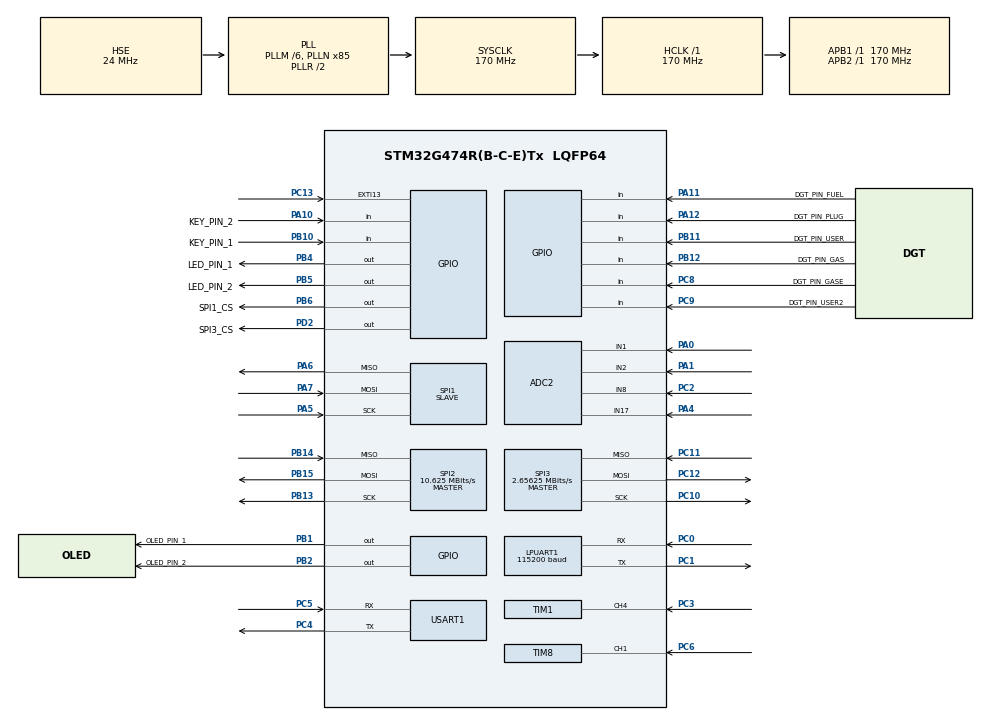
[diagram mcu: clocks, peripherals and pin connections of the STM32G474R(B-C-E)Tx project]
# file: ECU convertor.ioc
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ADC2.Channel-0\#ChannelRegularConversion=ADC_CHANNEL_1
ADC2.Channel-1\#ChannelRegularConversion=ADC_CHANNEL_2
ADC2.Channel-2\#ChannelRegularConversion=ADC_CHANNEL_8
ADC2.Channel-3\#ChannelRegularConversion=ADC_CHANNEL_17
ADC2.ContinuousConvMode=ENABLE
ADC2.DMAContinuousRequests=ENABLE
ADC2.EnableInjectedConversion=DISABLE
ADC2.NbrOfConversion=4
ADC2.NbrOfConversionFlag=1
ADC2.OffsetNumber-0\#ChannelRegularConversion=ADC_OFFSET_NONE
ADC2.OffsetNumber-1\#ChannelRegularConversion=ADC_OFFSET_NONE
ADC2.OffsetNumber-2\#ChannelRegularConversion=ADC_OFFSET_NONE
ADC2.OffsetNumber-3\#ChannelRegularConversion=ADC_OFFSET_NONE
ADC2.Rank-0\#ChannelRegularConversion=1
ADC2.Rank-1\#ChannelRegularConversion=2
ADC2.Rank-2\#ChannelRegularConversion=3
ADC2.Rank-3\#ChannelRegularConversion=4
ADC2.SamplingTime-0\#ChannelRegularConversion=ADC_SAMPLETIME_2CYCLES_5
ADC2.SamplingTime-1\#ChannelRegularConversion=ADC_SAMPLETIME_2CYCLES_5
ADC2.SamplingTime-2\#ChannelRegularConversion=ADC_SAMPLETIME_2CYCLES_5
ADC2.SamplingTime-3\#ChannelRegularConversion=ADC_SAMPLETIME_2CYCLES_5
Dma.ADC2.0.Direction=DMA_PERIPH_TO_MEMORY
Dma.ADC2.0.EventEnable=DISABLE
Dma.ADC2.0.Instance=DMA1_Channel1
Dma.ADC2.0.MemDataAlignment=DMA_MDATAALIGN_HALFWORD
Dma.ADC2.0.MemInc=DMA_MINC_ENABLE
Dma.ADC2.0.Mode=DMA_CIRCULAR
Dma.ADC2.0.PeriphDataAlignment=DMA_PDATAALIGN_HALFWORD
Dma.ADC2.0.PeriphInc=DMA_PINC_DISABLE
Dma.ADC2.0.Polarity=HAL_DMAMUX_REQ_GEN_RISING
Dma.ADC2.0.Priority=DMA_PRIORITY_LOW
Dma.ADC2.0.RequestNumber=1
Dma.ADC2.0.SignalID=NONE
Dma.ADC2.0.SyncEnable=DISABLE
Dma.ADC2.0.SyncPolarity=HAL_DMAMUX_SYNC_NO_EVENT
Dma.ADC2.0.SyncRequestNumber=1
Dma.ADC2.0.SyncSignalID=NONE
Dma.Request0=ADC2
LPUART1.BaudRate=115200
LPUART1.WordLength=UART_WORDLENGTH_8B
Mcu.Family=STM32G4
Mcu.Name=STM32G474R(B-C-E)Tx
Mcu.Package=LQFP64
NVIC.DMA1_Channel1_IRQn=true\:0\:0\:false\:false\:true\:false\:true
NVIC.EXTI15_10_IRQn=true\:0\:0\:false\:false\:true\:true\:true
NVIC.LPUART1_IRQn=true\:0\:0\:false\:false\:true\:true\:true
NVIC.PriorityGroup=NVIC_PRIORITYGROUP_4
NVIC.SPI1_IRQn=true\:0\:0\:false\:false\:true\:true\:true
NVIC.SPI2_IRQn=true\:0\:0\:false\:false\:true\:true\:true
NVIC.SPI3_IRQn=true\:0\:0\:false\:false\:true\:true\:true
NVIC.TIM6_DAC_IRQn=true\:0\:0\:false\:false\:true\:true\:true
NVIC.USART1_IRQn=true\:0\:0\:false\:false\:true\:true\:true
PA0.Mode=IN1-Single-Ended
PA0.Signal=ADC2_IN1
PA1.Mode=IN2-Single-Ended
PA1.Signal=ADC2_IN2
PA10.GPIO_Label=KEY_PIN_2
PA10.Signal=GPIO_Input
PA11.GPIO_Label=DGT_PIN_FUEL
PA11.Signal=GPIO_Input
PA12.GPIO_Label=DGT_PIN_PLUG
PA12.Signal=GPIO_Input
PA13.Mode=Serial_Wire
PA13.Signal=SYS_JTMS-SWDIO
PA14.Mode=Serial_Wire
PA14.Signal=SYS_JTCK-SWCLK
PA4.Mode=IN17-Single-Ended
PA4.Signal=ADC2_IN17
PA5.Mode=Full_Duplex_Slave
PA5.Signal=SPI1_SCK
PA6.Mode=Full_Duplex_Slave
PA6.Signal=SPI1_MISO
PA7.Mode=Full_Duplex_Slave
PA7.Signal=SPI1_MOSI
PB1.GPIO_Label=OLED_PIN_1
PB1.Signal=GPIO_Output
PB10.GPIO_Label=KEY_PIN_1
PB10.Signal=GPIO_Input
PB11.GPIO_Label=DGT_PIN_USER
PB11.Signal=GPIO_Input
PB12.GPIO_Label=DGT_PIN_GAS
PB12.Signal=GPIO_Input
PB13.Mode=Full_Duplex_Master
PB13.Signal=SPI2_SCK
PB14.Mode=Full_Duplex_Master
PB14.Signal=SPI2_MISO
PB15.Mode=Full_Duplex_Master
PB15.Signal=SPI2_MOSI
PB2.GPIO_Label=OLED_PIN_2
PB2.Signal=GPIO_Output
PB3.Signal=SYS_JTDO-SWO
PB4.GPIO_Label=LED_PIN_1
PB4.Signal=GPIO_Output
PB5.GPIO_Label=LED_PIN_2
PB5.Signal=GPIO_Output
PB6.GPIO_Label=SPI1_CS
PB6.Signal=GPIO_Output
PC0.Mode=Asynchronous
PC0.Signal=LPUART1_RX
PC1.Mode=Asynchronous
PC1.Signal=LPUART1_TX
PC10.Mode=Full_Duplex_Master
PC10.Signal=SPI3_SCK
PC11.Mode=Full_Duplex_Master
PC11.Signal=SPI3_MISO
PC12.Mode=Full_Duplex_Master
PC12.Signal=SPI3_MOSI
PC13.GPIO_ModeDefaultEXTI=GPIO_MODE_IT_RISING
PC13.GPIO_PuPd=GPIO_NOPULL
PC13.Signal=GPXTI13
PC14-OSC32_IN.Mode=LSE-External-Oscillator
PC14-OSC32_IN.Signal=RCC_OSC32_IN
PC15-OSC32_OUT.Mode=LSE-External-Oscillator
PC15-OSC32_OUT.Signal=RCC_OSC32_OUT
PC2.Mode=IN8-Single-Ended
PC2.Signal=ADC2_IN8
PC3.Signal=S_TIM1_CH4
PC4.GPIO_ModeDefaultPP=GPIO_MODE_AF_PP
PC4.GPIO_PuPd=GPIO_NOPULL
PC4.GPIO_Speed=GPIO_SPEED_FREQ_LOW
PC4.Mode=Asynchronous
PC4.Signal=USART1_TX
PC5.GPIO_ModeDefaultPP=GPIO_MODE_AF_PP
PC5.GPIO_PuPd=GPIO_NOPULL
PC5.GPIO_Speed=GPIO_SPEED_FREQ_LOW
PC5.Mode=Asynchronous
PC5.Signal=USART1_RX
PC6.Signal=S_TIM8_CH1
PC8.GPIO_Label=DGT_PIN_GASE
PC8.Signal=GPIO_Input
PC9.GPIO_Label=DGT_PIN_USER2
PC9.Signal=GPIO_Input
PD2.GPIO_Label=SPI3_CS
PD2.Signal=GPIO_Output
PF0-OSC_IN.Mode=HSE-External-Oscillator
PF0-OSC_IN.Signal=RCC_OSC_IN
PF1-OSC_OUT.Mode=HSE-External-Oscillator
PF1-OSC_OUT.Signal=RCC_OSC_OUT
ProjectManager.HeapSize=0x200
ProjectManager.StackSize=0x400
ProjectManager.TargetToolchain=MDK-ARM V5
RCC.ADC12Freq_Value=170000000
RCC.ADC345Freq_Value=170000000
RCC.AHBFreq_Value=170000000
RCC.APB1Freq_Value=170000000
RCC.APB1TimFreq_Value=170000000
RCC.APB2Freq_Value=170000000
RCC.APB2TimFreq_Value=170000000
RCC.CortexFreq_Value=170000000
RCC.EXTERNAL_CLOCK_VALUE=12288000
RCC.HCLKFreq_Value=170000000
RCC.HSE_VALUE=24000000
RCC.HSI48_VALUE=48000000
RCC.HSI_VALUE=16000000
RCC.PLLM=RCC_PLLM_DIV6
RCC.PLLN=85
RCC.PLLSourceVirtual=RCC_PLLSOURCE_HSE
RCC.RTCClockSelection=RCC_RTCCLKSOURCE_LSE
RCC.SYSCLKFreq_VALUE=170000000
RCC.SYSCLKSource=RCC_SYSCLKSOURCE_PLLCLK
RCC.USBFreq_Value=170000000
RCC.VCOOutputFreq_Value=340000000
SH.S_TIM1_CH4.0=TIM1_CH4,Input_Capture4_from_TI4
SH.S_TIM8_CH1.0=TIM8_CH1,Input_Capture1_from_TI1
SPI1.CLKPhase=SPI_PHASE_1EDGE
SPI1.DataSize=SPI_DATASIZE_16BIT
SPI1.Direction=SPI_DIRECTION_2LINES
SPI1.Mode=SPI_MODE_SLAVE
SPI1.VirtualNSS=VM_NSSHARD
SPI1.VirtualType=VM_SLAVE
SPI2.BaudRatePrescaler=SPI_BAUDRATEPRESCALER_16
SPI2.CLKPhase=SPI_PHASE_1EDGE
SPI2.CLKPolarity=SPI_POLARITY_HIGH
SPI2.CalculateBaudRate=10.625 MBits/s
SPI2.DataSize=SPI_DATASIZE_8BIT
SPI2.Direction=SPI_DIRECTION_2LINES
SPI2.Mode=SPI_MODE_MASTER
SPI2.VirtualType=VM_MASTER
SPI3.BaudRatePrescaler=SPI_BAUDRATEPRESCALER_64
SPI3.CLKPhase=SPI_PHASE_1EDGE
SPI3.CalculateBaudRate=2.65625 MBits/s
SPI3.DataSize=SPI_DATASIZE_16BIT
SPI3.Direction=SPI_DIRECTION_2LINES
SPI3.Mode=SPI_MODE_MASTER
SPI3.VirtualNSS=VM_NSSHARD
SPI3.VirtualType=VM_MASTER
TIM1.Channel-Input_Capture1_from_TI1=TIM_CHANNEL_1
TIM1.Channel-Input_Capture4_from_TI4=TIM_CHANNEL_4
TIM6.AutoReloadPreload=TIM_AUTORELOAD_PRELOAD_DISABLE
TIM6.PeriodNoDither=1000
TIM6.Prescaler=170
TIM8.AutoReloadPreload=TIM_AUTORELOAD_PRELOAD_DISABLE
TIM8.Channel-Input_Capture1_from_TI1=TIM_CHANNEL_1
TIM8.ICFilter_CH1=10
TIM8.ICPolarity_CH1=TIM_INPUTCHANNELPOLARITY_BOTHEDGE
TIM8.PeriodNoDither=1000-1
TIM8.Prescaler=170-1
USART1.VirtualMode-Asynchronous=VM_ASYNC
USART1.WordLength=WORDLENGTH_8B
VP_SYS_VS_DBSignals.Mode=DisableDeadBatterySignals
VP_TIM1_VS_ClockSourceINT.Mode=Internal
VP_TIM6_VS_ClockSourceINT.Mode=Enable_Timer
VP_TIM8_VS_ClockSourceINT.Mode=Internal
board=NUCLEO-G474RE

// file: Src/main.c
/* USER CODE BEGIN Header */
/**
  ******************************************************************************
  * @file           : main.c
  * @brief          : Main program body
  ******************************************************************************
  * @attention
  *
  * <h2><center>&copy; Copyright (c) 2020 STMicroelectronics.
  * All rights reserved.</center></h2>
  *
  * This software component is licensed by ST under BSD 3-Clause license,
  * the "License"; You may not use this file except in compliance with the
  * License. You may obtain a copy of the License at:
  *                        opensource.org/licenses/BSD-3-Clause
  *
  ******************************************************************************
  */
/* USER CODE END Header */

#include "main.h"

/* USER CODE BEGIN Includes */
#include "includes.h"
/* USER CODE END Includes */

ADC_HandleTypeDef hadc2;
DMA_HandleTypeDef hdma_adc2;

UART_HandleTypeDef hlpuart1;
UART_HandleTypeDef huart1;

SPI_HandleTypeDef hspi1;
SPI_HandleTypeDef hspi2;
SPI_HandleTypeDef hspi3;

TIM_HandleTypeDef htim1;
TIM_HandleTypeDef htim6;
TIM_HandleTypeDef htim8;

/* USER CODE BEGIN PV */
const SPI_CS_t USER_SPI_index[3] = {
		{ &hspi1, SPI1_CS_GPIO_Port, SPI1_CS_Pin },										//SPI MAP
		{ 0, 0, 0},
		{ &hspi2, SPI3_CS_GPIO_Port, SPI3_CS_Pin }
	};
/* USER CODE END PV */

void SystemClock_Config(void);
static void MX_GPIO_Init(void);
static void MX_DMA_Init(void);
static void MX_USART1_UART_Init(void);
static void MX_ADC2_Init(void);
static void MX_LPUART1_UART_Init(void);
static void MX_SPI1_Init(void);
static void MX_SPI2_Init(void);
static void MX_TIM1_Init(void);
static void MX_TIM8_Init(void);
static void MX_SPI3_Init(void);
static void MX_TIM6_Init(void);

int main(void)
{

  /* MCU Configuration--------------------------------------------------------*/

  /* Reset of all peripherals, Initializes the Flash interface and the Systick. */
  HAL_Init();

  /* Configure the system clock */
  SystemClock_Config();

  /* Initialize all configured peripherals */
  MX_GPIO_Init();
  MX_DMA_Init();
  MX_USART1_UART_Init();
  MX_ADC2_Init();
  MX_LPUART1_UART_Init();
  MX_SPI1_Init();
  MX_SPI2_Init();
  MX_TIM1_Init();
  MX_TIM8_Init();
  MX_SPI3_Init();
  MX_TIM6_Init();
  /* USER CODE BEGIN 2 */
	init_ADC(&hadc2);

	init_debug();
	init_Esp8266();

  /* USER CODE END 2 */

  /* Infinite loop */
  while (1)
  {

    /* USER CODE BEGIN 3 */
		HAL_GPIO_TogglePin(LED_PIN_2_GPIO_Port, LED_PIN_2_Pin);
		//HAL_UART_Transmit(&huart_esp, "AT\r\n", 5, 1000);
		esp_transmit("123\r\n",6);
		//analog_monitor();
		//if(HAL_OK == HAL_UART_Transmit(&hlpuart1, "�첩ʿ̫˧��\r\n", 15, 1000)) HAL_GPIO_TogglePin (LED_PIN_1_GPIO_Port, LED_PIN_1_Pin);
		HAL_Delay(1000);
  }
  /* USER CODE END 3 */
}

void SystemClock_Config(void)
{
  RCC_OscInitTypeDef RCC_OscInitStruct = {0};
  RCC_ClkInitTypeDef RCC_ClkInitStruct = {0};
  RCC_PeriphCLKInitTypeDef PeriphClkInit = {0};

  /** Configure the main internal regulator output voltage
  */
  HAL_PWREx_ControlVoltageScaling(PWR_REGULATOR_VOLTAGE_SCALE1_BOOST);
  /** Initializes the CPU, AHB and APB busses clocks
  */
  RCC_OscInitStruct.OscillatorType = RCC_OSCILLATORTYPE_HSE;
  RCC_OscInitStruct.HSEState = RCC_HSE_ON;
  RCC_OscInitStruct.PLL.PLLState = RCC_PLL_ON;
  RCC_OscInitStruct.PLL.PLLSource = RCC_PLLSOURCE_HSE;
  RCC_OscInitStruct.PLL.PLLM = RCC_PLLM_DIV6;
  RCC_OscInitStruct.PLL.PLLN = 85;
  RCC_OscInitStruct.PLL.PLLP = RCC_PLLP_DIV2;
  RCC_OscInitStruct.PLL.PLLQ = RCC_PLLQ_DIV2;
  RCC_OscInitStruct.PLL.PLLR = RCC_PLLR_DIV2;
  if (HAL_RCC_OscConfig(&RCC_OscInitStruct) != HAL_OK)
  {
    Error_Handler();
  }
  /** Initializes the CPU, AHB and APB busses clocks
  */
  RCC_ClkInitStruct.ClockType = RCC_CLOCKTYPE_HCLK|RCC_CLOCKTYPE_SYSCLK
                              |RCC_CLOCKTYPE_PCLK1|RCC_CLOCKTYPE_PCLK2;
  RCC_ClkInitStruct.SYSCLKSource = RCC_SYSCLKSOURCE_PLLCLK;
  RCC_ClkInitStruct.AHBCLKDivider = RCC_SYSCLK_DIV1;
  RCC_ClkInitStruct.APB1CLKDivider = RCC_HCLK_DIV1;
  RCC_ClkInitStruct.APB2CLKDivider = RCC_HCLK_DIV1;

  if (HAL_RCC_ClockConfig(&RCC_ClkInitStruct, FLASH_LATENCY_8) != HAL_OK)
  {
    Error_Handler();
  }
  /** Initializes the peripherals clocks
  */
  PeriphClkInit.PeriphClockSelection = RCC_PERIPHCLK_USART1|RCC_PERIPHCLK_LPUART1
                              |RCC_PERIPHCLK_ADC12;
  PeriphClkInit.Usart1ClockSelection = RCC_USART1CLKSOURCE_PCLK2;
  PeriphClkInit.Lpuart1ClockSelection = RCC_LPUART1CLKSOURCE_PCLK1;
  PeriphClkInit.Adc12ClockSelection = RCC_ADC12CLKSOURCE_SYSCLK;
  if (HAL_RCCEx_PeriphCLKConfig(&PeriphClkInit) != HAL_OK)
  {
    Error_Handler();
  }
}

static void MX_ADC2_Init(void)
{

  ADC_ChannelConfTypeDef sConfig = {0};

  /** Common config
  */
  hadc2.Instance = ADC2;
  hadc2.Init.ClockPrescaler = ADC_CLOCK_ASYNC_DIV1;
  hadc2.Init.Resolution = ADC_RESOLUTION_12B;
  hadc2.Init.DataAlign = ADC_DATAALIGN_RIGHT;
  hadc2.Init.GainCompensation = 0;
  hadc2.Init.ScanConvMode = ADC_SCAN_ENABLE;
  hadc2.Init.EOCSelection = ADC_EOC_SINGLE_CONV;
  hadc2.Init.LowPowerAutoWait = DISABLE;
  hadc2.Init.ContinuousConvMode = ENABLE;
  hadc2.Init.NbrOfConversion = 4;
  hadc2.Init.DiscontinuousConvMode = DISABLE;
  hadc2.Init.ExternalTrigConv = ADC_SOFTWARE_START;
  hadc2.Init.ExternalTrigConvEdge = ADC_EXTERNALTRIGCONVEDGE_NONE;
  hadc2.Init.DMAContinuousRequests = ENABLE;
  hadc2.Init.Overrun = ADC_OVR_DATA_PRESERVED;
  hadc2.Init.OversamplingMode = DISABLE;
  if (HAL_ADC_Init(&hadc2) != HAL_OK)
  {
    Error_Handler();
  }
  /** Configure Regular Channel
  */
  sConfig.Channel = ADC_CHANNEL_1;
  sConfig.Rank = ADC_REGULAR_RANK_1;
  sConfig.SamplingTime = ADC_SAMPLETIME_2CYCLES_5;
  sConfig.SingleDiff = ADC_SINGLE_ENDED;
  sConfig.OffsetNumber = ADC_OFFSET_NONE;
  sConfig.Offset = 0;
  if (HAL_ADC_ConfigChannel(&hadc2, &sConfig) != HAL_OK)
  {
    Error_Handler();
  }
  /** Configure Regular Channel
  */
  sConfig.Channel = ADC_CHANNEL_2;
  sConfig.Rank = ADC_REGULAR_RANK_2;
  if (HAL_ADC_ConfigChannel(&hadc2, &sConfig) != HAL_OK)
  {
    Error_Handler();
  }
  /** Configure Regular Channel
  */
  sConfig.Channel = ADC_CHANNEL_8;
  sConfig.Rank = ADC_REGULAR_RANK_3;
  if (HAL_ADC_ConfigChannel(&hadc2, &sConfig) != HAL_OK)
  {
    Error_Handler();
  }
  /** Configure Regular Channel
  */
  sConfig.Channel = ADC_CHANNEL_17;
  sConfig.Rank = ADC_REGULAR_RANK_4;
  if (HAL_ADC_ConfigChannel(&hadc2, &sConfig) != HAL_OK)
  {
    Error_Handler();
  }

}

static void MX_LPUART1_UART_Init(void)
{

  hlpuart1.Instance = LPUART1;
  hlpuart1.Init.BaudRate = 115200;
  hlpuart1.Init.WordLength = UART_WORDLENGTH_8B;
  hlpuart1.Init.StopBits = UART_STOPBITS_1;
  hlpuart1.Init.Parity = UART_PARITY_NONE;
  hlpuart1.Init.Mode = UART_MODE_TX_RX;
  hlpuart1.Init.HwFlowCtl = UART_HWCONTROL_NONE;
  hlpuart1.Init.OneBitSampling = UART_ONE_BIT_SAMPLE_DISABLE;
  hlpuart1.AdvancedInit.AdvFeatureInit = UART_ADVFEATURE_NO_INIT;
  if (HAL_UART_Init(&hlpuart1) != HAL_OK)
  {
    Error_Handler();
  }
  if (HAL_UARTEx_SetTxFifoThreshold(&hlpuart1, UART_TXFIFO_THRESHOLD_1_8) != HAL_OK)
  {
    Error_Handler();
  }
  if (HAL_UARTEx_SetRxFifoThreshold(&hlpuart1, UART_RXFIFO_THRESHOLD_1_8) != HAL_OK)
  {
    Error_Handler();
  }
  if (HAL_UARTEx_DisableFifoMode(&hlpuart1) != HAL_OK)
  {
    Error_Handler();
  }

}

static void MX_USART1_UART_Init(void)
{

  huart1.Instance = USART1;
  huart1.Init.BaudRate = 115200;
  huart1.Init.WordLength = UART_WORDLENGTH_8B;
  huart1.Init.StopBits = UART_STOPBITS_1;
  huart1.Init.Parity = UART_PARITY_NONE;
  huart1.Init.Mode = UART_MODE_TX_RX;
  huart1.Init.HwFlowCtl = UART_HWCONTROL_NONE;
  huart1.Init.OverSampling = UART_OVERSAMPLING_16;
  huart1.Init.OneBitSampling = UART_ONE_BIT_SAMPLE_DISABLE;
  huart1.Init.ClockPrescaler = UART_PRESCALER_DIV1;
  huart1.AdvancedInit.AdvFeatureInit = UART_ADVFEATURE_NO_INIT;
  if (HAL_UART_Init(&huart1) != HAL_OK)
  {
    Error_Handler();
  }
  if (HAL_UARTEx_SetTxFifoThreshold(&huart1, UART_TXFIFO_THRESHOLD_1_8) != HAL_OK)
  {
    Error_Handler();
  }
  if (HAL_UARTEx_SetRxFifoThreshold(&huart1, UART_RXFIFO_THRESHOLD_1_8) != HAL_OK)
  {
    Error_Handler();
  }
  if (HAL_UARTEx_DisableFifoMode(&huart1) != HAL_OK)
  {
    Error_Handler();
  }

}

static void MX_SPI1_Init(void)
{

  /* SPI1 parameter configuration*/
  hspi1.Instance = SPI1;
  hspi1.Init.Mode = SPI_MODE_SLAVE;
  hspi1.Init.Direction = SPI_DIRECTION_2LINES;
  hspi1.Init.DataSize = SPI_DATASIZE_16BIT;
  hspi1.Init.CLKPolarity = SPI_POLARITY_LOW;
  hspi1.Init.CLKPhase = SPI_PHASE_1EDGE;
  hspi1.Init.NSS = SPI_NSS_SOFT;
  hspi1.Init.FirstBit = SPI_FIRSTBIT_MSB;
  hspi1.Init.TIMode = SPI_TIMODE_DISABLE;
  hspi1.Init.CRCCalculation = SPI_CRCCALCULATION_DISABLE;
  hspi1.Init.CRCPolynomial = 7;
  hspi1.Init.CRCLength = SPI_CRC_LENGTH_DATASIZE;
  hspi1.Init.NSSPMode = SPI_NSS_PULSE_DISABLE;
  if (HAL_SPI_Init(&hspi1) != HAL_OK)
  {
    Error_Handler();
  }

}

static void MX_SPI2_Init(void)
{

  /* SPI2 parameter configuration*/
  hspi2.Instance = SPI2;
  hspi2.Init.Mode = SPI_MODE_MASTER;
  hspi2.Init.Direction = SPI_DIRECTION_2LINES;
  hspi2.Init.DataSize = SPI_DATASIZE_8BIT;
  hspi2.Init.CLKPolarity = SPI_POLARITY_HIGH;
  hspi2.Init.CLKPhase = SPI_PHASE_1EDGE;
  hspi2.Init.NSS = SPI_NSS_SOFT;
  hspi2.Init.BaudRatePrescaler = SPI_BAUDRATEPRESCALER_16;
  hspi2.Init.FirstBit = SPI_FIRSTBIT_MSB;
  hspi2.Init.TIMode = SPI_TIMODE_DISABLE;
  hspi2.Init.CRCCalculation = SPI_CRCCALCULATION_DISABLE;
  hspi2.Init.CRCPolynomial = 7;
  hspi2.Init.CRCLength = SPI_CRC_LENGTH_DATASIZE;
  hspi2.Init.NSSPMode = SPI_NSS_PULSE_ENABLE;
  if (HAL_SPI_Init(&hspi2) != HAL_OK)
  {
    Error_Handler();
  }

}

static void MX_SPI3_Init(void)
{

  /* SPI3 parameter configuration*/
  hspi3.Instance = SPI3;
  hspi3.Init.Mode = SPI_MODE_MASTER;
  hspi3.Init.Direction = SPI_DIRECTION_2LINES;
  hspi3.Init.DataSize = SPI_DATASIZE_16BIT;
  hspi3.Init.CLKPolarity = SPI_POLARITY_LOW;
  hspi3.Init.CLKPhase = SPI_PHASE_1EDGE;
  hspi3.Init.NSS = SPI_NSS_SOFT;
  hspi3.Init.BaudRatePrescaler = SPI_BAUDRATEPRESCALER_64;
  hspi3.Init.FirstBit = SPI_FIRSTBIT_MSB;
  hspi3.Init.TIMode = SPI_TIMODE_DISABLE;
  hspi3.Init.CRCCalculation = SPI_CRCCALCULATION_DISABLE;
  hspi3.Init.CRCPolynomial = 7;
  hspi3.Init.CRCLength = SPI_CRC_LENGTH_DATASIZE;
  hspi3.Init.NSSPMode = SPI_NSS_PULSE_ENABLE;
  if (HAL_SPI_Init(&hspi3) != HAL_OK)
  {
    Error_Handler();
  }

}

static void MX_TIM1_Init(void)
{

  TIM_ClockConfigTypeDef sClockSourceConfig = {0};
  TIM_MasterConfigTypeDef sMasterConfig = {0};
  TIM_IC_InitTypeDef sConfigIC = {0};
  TIM_BreakDeadTimeConfigTypeDef sBreakDeadTimeConfig = {0};

  htim1.Instance = TIM1;
  htim1.Init.Prescaler = 0;
  htim1.Init.CounterMode = TIM_COUNTERMODE_UP;
  htim1.Init.Period = 0;
  htim1.Init.ClockDivision = TIM_CLOCKDIVISION_DIV1;
  htim1.Init.RepetitionCounter = 0;
  htim1.Init.AutoReloadPreload = TIM_AUTORELOAD_PRELOAD_DISABLE;
  if (HAL_TIM_Base_Init(&htim1) != HAL_OK)
  {
    Error_Handler();
  }
  sClockSourceConfig.ClockSource = TIM_CLOCKSOURCE_INTERNAL;
  if (HAL_TIM_ConfigClockSource(&htim1, &sClockSourceConfig) != HAL_OK)
  {
    Error_Handler();
  }
  if (HAL_TIM_IC_Init(&htim1) != HAL_OK)
  {
    Error_Handler();
  }
  sMasterConfig.MasterOutputTrigger = TIM_TRGO_RESET;
  sMasterConfig.MasterOutputTrigger2 = TIM_TRGO2_RESET;
  sMasterConfig.MasterSlaveMode = TIM_MASTERSLAVEMODE_DISABLE;
  if (HAL_TIMEx_MasterConfigSynchronization(&htim1, &sMasterConfig) != HAL_OK)
  {
    Error_Handler();
  }
  sConfigIC.ICPolarity = TIM_INPUTCHANNELPOLARITY_RISING;
  sConfigIC.ICSelection = TIM_ICSELECTION_DIRECTTI;
  sConfigIC.ICPrescaler = TIM_ICPSC_DIV1;
  sConfigIC.ICFilter = 0;
  if (HAL_TIM_IC_ConfigChannel(&htim1, &sConfigIC, TIM_CHANNEL_4) != HAL_OK)
  {
    Error_Handler();
  }
  sBreakDeadTimeConfig.BreakAFMode = TIM_BREAK_AFMODE_INPUT;
  sBreakDeadTimeConfig.Break2AFMode = TIM_BREAK_AFMODE_INPUT;
  if (HAL_TIMEx_ConfigBreakDeadTime(&htim1, &sBreakDeadTimeConfig) != HAL_OK)
  {
    Error_Handler();
  }

}

static void MX_TIM6_Init(void)
{

  TIM_MasterConfigTypeDef sMasterConfig = {0};

  htim6.Instance = TIM6;
  htim6.Init.Prescaler = 170;
  htim6.Init.CounterMode = TIM_COUNTERMODE_UP;
  htim6.Init.Period = 1000;
  htim6.Init.AutoReloadPreload = TIM_AUTORELOAD_PRELOAD_DISABLE;
  if (HAL_TIM_Base_Init(&htim6) != HAL_OK)
  {
    Error_Handler();
  }
  sMasterConfig.MasterOutputTrigger = TIM_TRGO_RESET;
  sMasterConfig.MasterSlaveMode = TIM_MASTERSLAVEMODE_DISABLE;
  if (HAL_TIMEx_MasterConfigSynchronization(&htim6, &sMasterConfig) != HAL_OK)
  {
    Error_Handler();
  }

}

static void MX_TIM8_Init(void)
{

  TIM_ClockConfigTypeDef sClockSourceConfig = {0};
  TIM_MasterConfigTypeDef sMasterConfig = {0};
  TIM_IC_InitTypeDef sConfigIC = {0};
  TIM_BreakDeadTimeConfigTypeDef sBreakDeadTimeConfig = {0};

  htim8.Instance = TIM8;
  htim8.Init.Prescaler = 170-1;
  htim8.Init.CounterMode = TIM_COUNTERMODE_UP;
  htim8.Init.Period = 999;
  htim8.Init.ClockDivision = TIM_CLOCKDIVISION_DIV1;
  htim8.Init.RepetitionCounter = 0;
  htim8.Init.AutoReloadPreload = TIM_AUTORELOAD_PRELOAD_DISABLE;
  if (HAL_TIM_Base_Init(&htim8) != HAL_OK)
  {
    Error_Handler();
  }
  sClockSourceConfig.ClockSource = TIM_CLOCKSOURCE_INTERNAL;
  if (HAL_TIM_ConfigClockSource(&htim8, &sClockSourceConfig) != HAL_OK)
  {
    Error_Handler();
  }
  if (HAL_TIM_IC_Init(&htim8) != HAL_OK)
  {
    Error_Handler();
  }
  sMasterConfig.MasterOutputTrigger = TIM_TRGO_RESET;
  sMasterConfig.MasterOutputTrigger2 = TIM_TRGO2_RESET;
  sMasterConfig.MasterSlaveMode = TIM_MASTERSLAVEMODE_DISABLE;
  if (HAL_TIMEx_MasterConfigSynchronization(&htim8, &sMasterConfig) != HAL_OK)
  {
    Error_Handler();
  }
  sConfigIC.ICPolarity = TIM_INPUTCHANNELPOLARITY_BOTHEDGE;
  sConfigIC.ICSelection = TIM_ICSELECTION_DIRECTTI;
  sConfigIC.ICPrescaler = TIM_ICPSC_DIV1;
  sConfigIC.ICFilter = 10;
  if (HAL_TIM_IC_ConfigChannel(&htim8, &sConfigIC, TIM_CHANNEL_1) != HAL_OK)
  {
    Error_Handler();
  }
  sBreakDeadTimeConfig.BreakAFMode = TIM_BREAK_AFMODE_INPUT;
  sBreakDeadTimeConfig.Break2AFMode = TIM_BREAK_AFMODE_INPUT;
  if (HAL_TIMEx_ConfigBreakDeadTime(&htim8, &sBreakDeadTimeConfig) != HAL_OK)
  {
    Error_Handler();
  }

}

static void MX_DMA_Init(void)
{

  /* DMA controller clock enable */
  __HAL_RCC_DMAMUX1_CLK_ENABLE();
  __HAL_RCC_DMA1_CLK_ENABLE();

  /* DMA interrupt init */
  /* DMA1_Channel1_IRQn interrupt configuration */
  HAL_NVIC_SetPriority(DMA1_Channel1_IRQn, 0, 0);
  HAL_NVIC_EnableIRQ(DMA1_Channel1_IRQn);

}

static void MX_GPIO_Init(void)
{
  GPIO_InitTypeDef GPIO_InitStruct = {0};

  /* GPIO Ports Clock Enable */
  __HAL_RCC_GPIOC_CLK_ENABLE();
  __HAL_RCC_GPIOF_CLK_ENABLE();
  __HAL_RCC_GPIOA_CLK_ENABLE();
  __HAL_RCC_GPIOB_CLK_ENABLE();
  __HAL_RCC_GPIOD_CLK_ENABLE();

  /*Configure GPIO pin Output Level */
  HAL_GPIO_WritePin(GPIOB, OLED_PIN_1_Pin|OLED_PIN_2_Pin|LED_PIN_1_Pin|LED_PIN_2_Pin
                          |SPI1_CS_Pin, GPIO_PIN_RESET);

  /*Configure GPIO pin Output Level */
  HAL_GPIO_WritePin(SPI3_CS_GPIO_Port, SPI3_CS_Pin, GPIO_PIN_RESET);

  /*Configure GPIO pin : PC13 */
  GPIO_InitStruct.Pin = GPIO_PIN_13;
  GPIO_InitStruct.Mode = GPIO_MODE_IT_RISING;
  GPIO_InitStruct.Pull = GPIO_NOPULL;
  HAL_GPIO_Init(GPIOC, &GPIO_InitStruct);

  /*Configure GPIO pins : OLED_PIN_1_Pin OLED_PIN_2_Pin LED_PIN_1_Pin LED_PIN_2_Pin
                           SPI1_CS_Pin */
  GPIO_InitStruct.Pin = OLED_PIN_1_Pin|OLED_PIN_2_Pin|LED_PIN_1_Pin|LED_PIN_2_Pin
                          |SPI1_CS_Pin;
  GPIO_InitStruct.Mode = GPIO_MODE_OUTPUT_PP;
  GPIO_InitStruct.Pull = GPIO_NOPULL;
  GPIO_InitStruct.Speed = GPIO_SPEED_FREQ_LOW;
  HAL_GPIO_Init(GPIOB, &GPIO_InitStruct);

  /*Configure GPIO pins : KEY_PIN_1_Pin DGT_PIN_USER_Pin DGT_PIN_GAS_Pin */
  GPIO_InitStruct.Pin = KEY_PIN_1_Pin|DGT_PIN_USER_Pin|DGT_PIN_GAS_Pin;
  GPIO_InitStruct.Mode = GPIO_MODE_INPUT;
  GPIO_InitStruct.Pull = GPIO_NOPULL;
  HAL_GPIO_Init(GPIOB, &GPIO_InitStruct);

  /*Configure GPIO pins : DGT_PIN_GASE_Pin DGT_PIN_USER2_Pin */
  GPIO_InitStruct.Pin = DGT_PIN_GASE_Pin|DGT_PIN_USER2_Pin;
  GPIO_InitStruct.Mode = GPIO_MODE_INPUT;
  GPIO_InitStruct.Pull = GPIO_NOPULL;
  HAL_GPIO_Init(GPIOC, &GPIO_InitStruct);

  /*Configure GPIO pins : KEY_PIN_2_Pin DGT_PIN_FUEL_Pin DGT_PIN_PLUG_Pin */
  GPIO_InitStruct.Pin = KEY_PIN_2_Pin|DGT_PIN_FUEL_Pin|DGT_PIN_PLUG_Pin;
  GPIO_InitStruct.Mode = GPIO_MODE_INPUT;
  GPIO_InitStruct.Pull = GPIO_NOPULL;
  HAL_GPIO_Init(GPIOA, &GPIO_InitStruct);

  /*Configure GPIO pin : SPI3_CS_Pin */
  GPIO_InitStruct.Pin = SPI3_CS_Pin;
  GPIO_InitStruct.Mode = GPIO_MODE_OUTPUT_PP;
  GPIO_InitStruct.Pull = GPIO_NOPULL;
  GPIO_InitStruct.Speed = GPIO_SPEED_FREQ_LOW;
  HAL_GPIO_Init(SPI3_CS_GPIO_Port, &GPIO_InitStruct);

  /* EXTI interrupt init*/
  HAL_NVIC_SetPriority(EXTI15_10_IRQn, 0, 0);
  HAL_NVIC_EnableIRQ(EXTI15_10_IRQn);

}

void Error_Handler(void)
{
}

/************************ (C) COPYRIGHT STMicroelectronics *****END OF FILE****/
